# M440 register map
File version: 0.1
Registers are 32-bit, read-write, reset 0x0 unless marked. A register's access mark holds for its fields unless they carry their own. Offsets are from the block's base; [hi:lo] are bit positions; {n}, {i} and the like mark numbered series.

## PN — Port N
Base 0x400C0C00
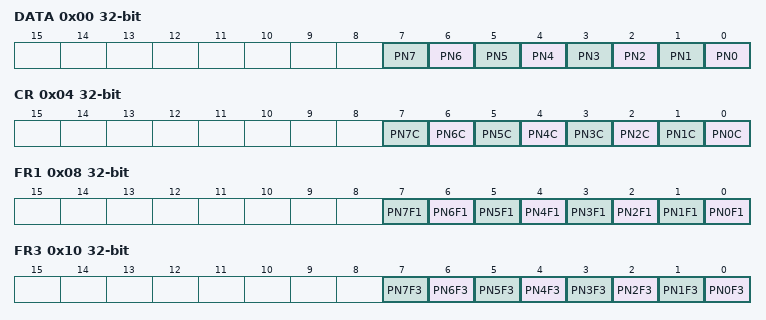
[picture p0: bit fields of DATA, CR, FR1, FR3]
0x00 DATA — Port N Data Register
  [n] PN{n} (n=0..7)
0x04 CR — Port N Output Control Register
  [n] PN{n}C (n=0..7)
0x08 FR1 — Port N Function Register 1
  [n] PN{n}F1 (n=0..7)
0x10 FR3 — Port N Function Register 3
  [n] PN{n}F3 (n=0..7)
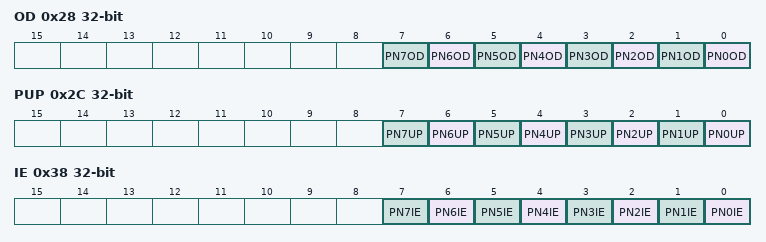
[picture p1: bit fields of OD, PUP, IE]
0x28 OD — Port N Open Drain Control Register
  [n] PN{n}OD (n=0..7)
0x2C PUP — Port N Pull-up Control Register
  [n] PN{n}UP (n=0..7)
0x38 IE — Port N Input Control Register
  [n] PN{n}IE (n=0..7)

## PP — Port P
Base 0x400C0D00
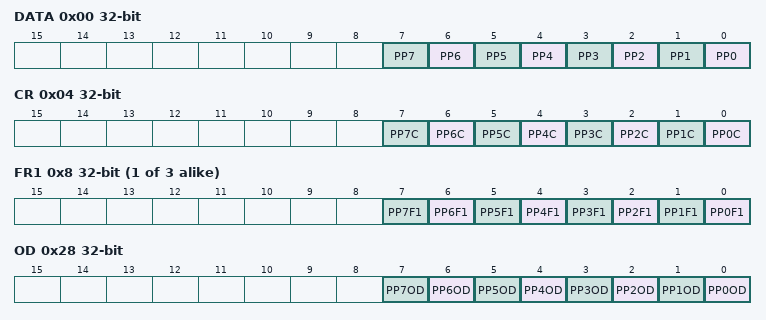
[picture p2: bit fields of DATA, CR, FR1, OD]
0x00 DATA — Port P Data Register
  [n] PP{n} (n=0..7)
0x04 CR — Port P Output Control Register
  [n] PP{n}C (n=0..7)
{0x4+4i} FR{i} (i=1..3) — Port P Function Register {i}
  [n] PP{n}F{i} (n=0..7)
0x28 OD — Port P Open Drain Control Register
  [n] PP{n}OD (n=0..7)
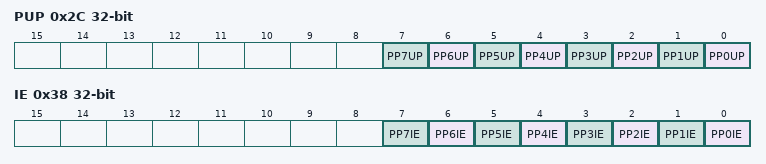
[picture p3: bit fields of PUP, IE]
0x2C PUP — Port P Pull-up Control Register
  [n] PP{n}UP (n=0..7)
0x38 IE — Port P Input Control Register
  [n] PP{n}IE (n=0..7)

## PR — Port R
Base 0x400C0E00
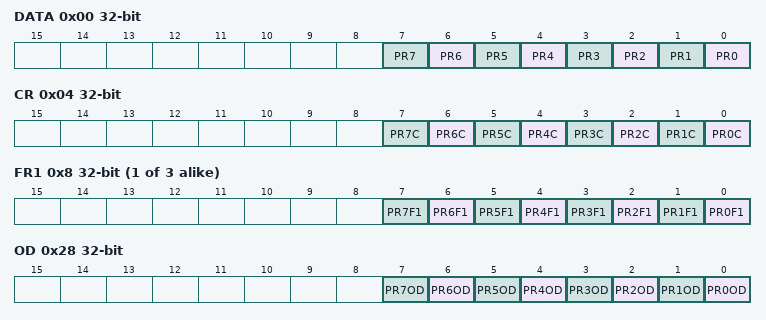
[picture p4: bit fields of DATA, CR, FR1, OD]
0x00 DATA — Port R Data Register
  [n] PR{n} (n=0..7)
0x04 CR — Port R Output Control Register
  [n] PR{n}C (n=0..7)
{0x4+4i} FR{i} (i=1..3) — Port R Function Register {i}
  [n] PR{n}F{i} (n=0..7)
0x28 OD — Port R Open Drain Control Register
  [n] PR{n}OD (n=0..7)
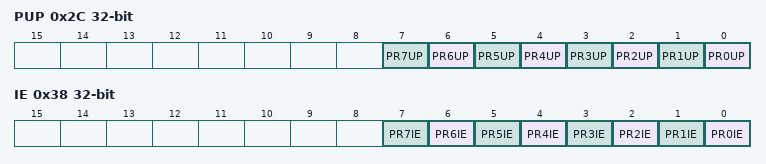
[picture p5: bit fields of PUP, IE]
0x2C PUP — Port R Pull-up Control Register
  [n] PR{n}UP (n=0..7)
0x38 IE — Port R Input Control Register
  [n] PR{n}IE (n=0..7)

## PT — Port T
Base 0x400C0F00
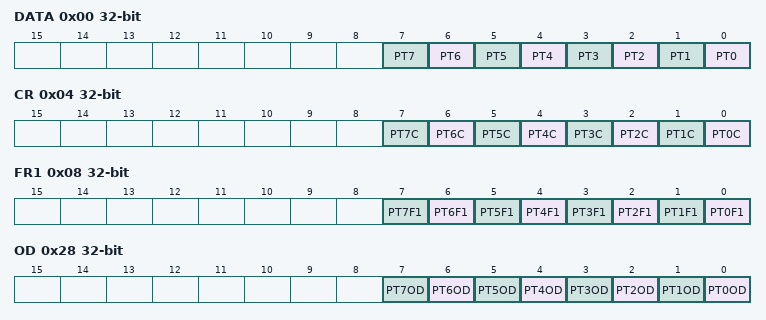
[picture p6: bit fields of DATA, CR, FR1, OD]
0x00 DATA — Port T Data Register
  [n] PT{n} (n=0..7)
0x04 CR — Port T Output Control Register
  [n] PT{n}C (n=0..7)
0x08 FR1 — Port T Function Register 1
  [n] PT{n}F1 (n=0..7)
0x28 OD — Port T Open Drain Control Register
  [n] PT{n}OD (n=0..7)
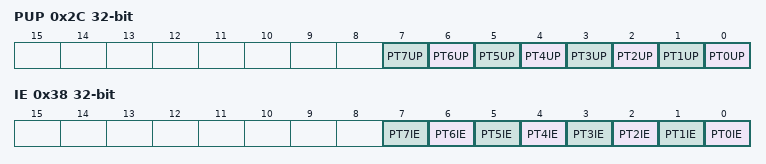
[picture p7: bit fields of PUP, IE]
0x2C PUP — Port T Pull-up Control Register
  [n] PT{n}UP (n=0..7)
0x38 IE — Port T Input Control Register
  [n] PT{n}IE (n=0..7)

## PU — Port U
Base 0x400C1000
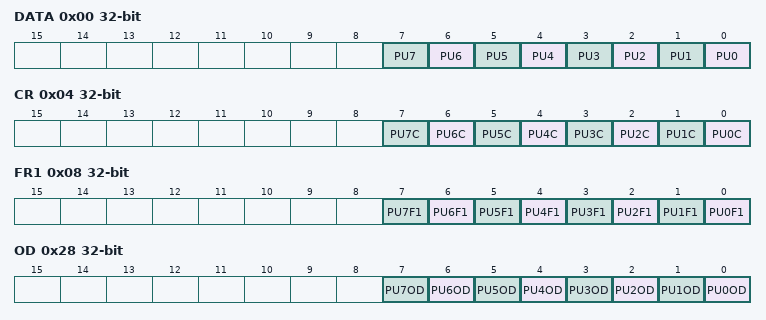
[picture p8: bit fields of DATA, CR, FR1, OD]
0x00 DATA — Port U Data Register
  [n] PU{n} (n=0..7)
0x04 CR — Port U Output Control Register
  [n] PU{n}C (n=0..7)
0x08 FR1 — Port U Function Register 1
  [n] PU{n}F1 (n=0..7)
0x28 OD — Port U Open Drain Control Register
  [n] PU{n}OD (n=0..7)
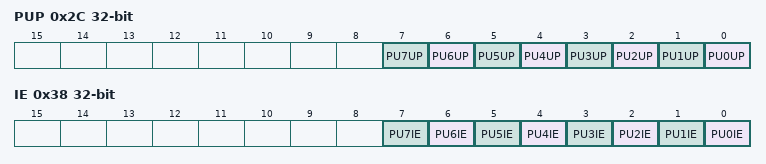
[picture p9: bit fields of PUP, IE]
0x2C PUP — Port U Pull-up Control Register
  [n] PU{n}UP (n=0..7)
0x38 IE — Port U Input Control Register
  [n] PU{n}IE (n=0..7)

## PV — Port V
Base 0x400C1100
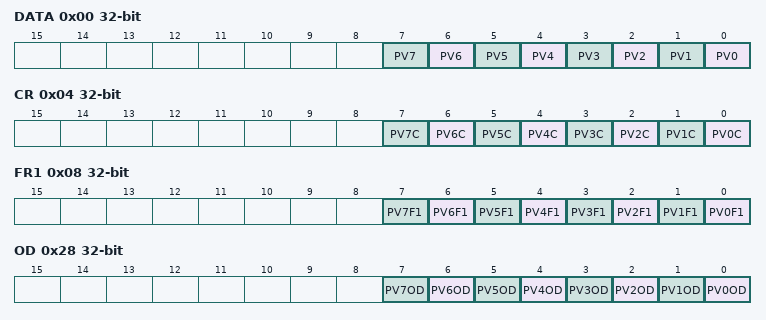
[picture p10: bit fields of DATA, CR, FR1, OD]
0x00 DATA — Port V Data Register
  [n] PV{n} (n=0..7)
0x04 CR — Port V OutPVt Control Register
  [n] PV{n}C (n=0..7)
0x08 FR1 — Port V Function Register 1
  [n] PV{n}F1 (n=0..7)
0x28 OD — Port V Open Drain Control Register
  [n] PV{n}OD (n=0..7)
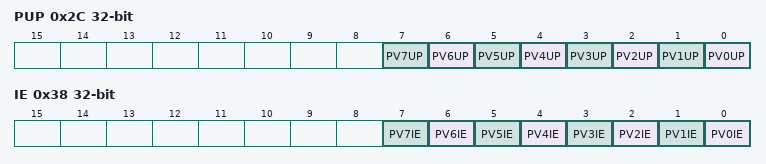
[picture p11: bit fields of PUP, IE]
0x2C PUP — Port V PVll-up Control Register
  [n] PV{n}UP (n=0..7)
0x38 IE — Port V InPVt Control Register
  [n] PV{n}IE (n=0..7)

## PW — Port W
Base 0x400C1200
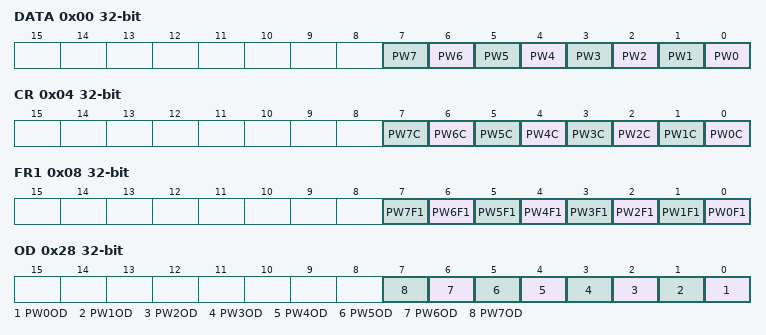
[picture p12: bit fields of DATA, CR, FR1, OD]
0x00 DATA — Port W Data Register
  [n] PW{n} (n=0..7)
0x04 CR — Port W OutPWt Control Register
  [n] PW{n}C (n=0..7)
0x08 FR1 — Port W Function Register 1
  [n] PW{n}F1 (n=0..7)
0x28 OD — Port W Open Drain Control Register
  [n] PW{n}OD (n=0..7)
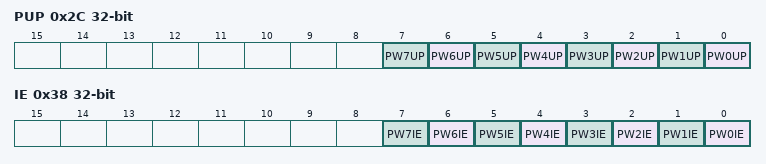
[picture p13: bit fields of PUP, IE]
0x2C PUP — Port W PWll-up Control Register
  [n] PW{n}UP (n=0..7)
0x38 IE — Port W InPWt Control Register
  [n] PW{n}IE (n=0..7)

## PY — Port Y
Base 0x400C1300
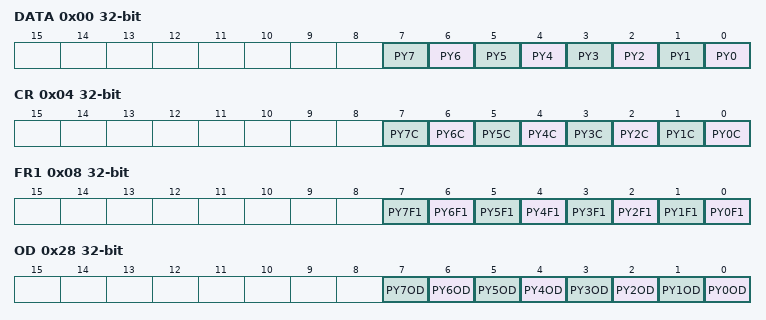
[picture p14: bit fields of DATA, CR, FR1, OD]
0x00 DATA — Port Y Data Register
  [n] PY{n} (n=0..7)
0x04 CR — Port Y OutPYt Control Register
  [n] PY{n}C (n=0..7)
0x08 FR1 — Port Y Function Register 1
  [n] PY{n}F1 (n=0..7)
0x28 OD — Port Y Open Drain Control Register
  [n] PY{n}OD (n=0..7)
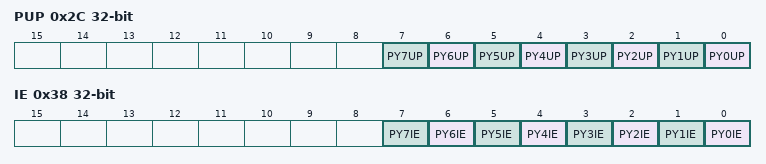
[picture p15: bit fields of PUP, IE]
0x2C PUP — Port Y PYll-up Control Register
  [n] PY{n}UP (n=0..7)
0x38 IE — Port Y InPYt Control Register
  [n] PY{n}IE (n=0..7)

## PAA — Port AA
Base 0x400C1400
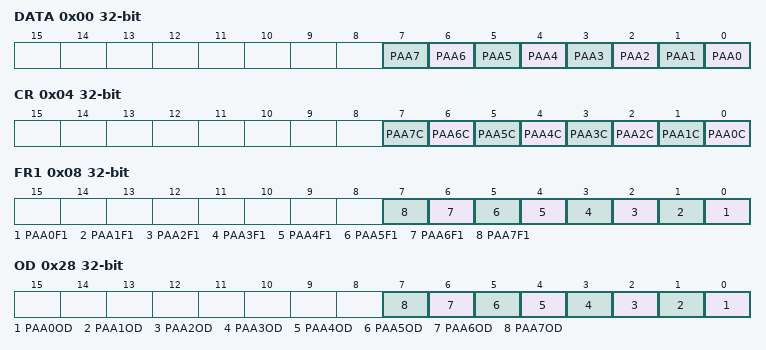
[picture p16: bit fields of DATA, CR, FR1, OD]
0x00 DATA — Port AA Data Register
  [n] PAA{n} (n=0..7)
0x04 CR — Port AA OutPAAt Control Register
  [n] PAA{n}C (n=0..7)
0x08 FR1 — Port AA Function Register 1
  [n] PAA{n}F1 (n=0..7)
0x28 OD — Port AA Open Drain Control Register
  [n] PAA{n}OD (n=0..7)
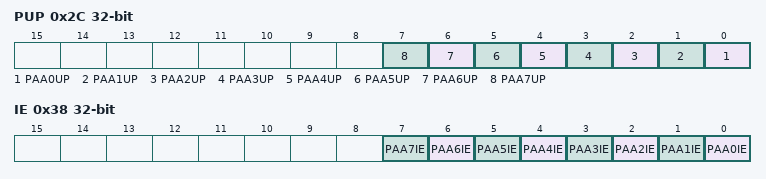
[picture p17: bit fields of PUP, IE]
0x2C PUP — Port AA PAAll-up Control Register
  [n] PAA{n}UP (n=0..7)
0x38 IE — Port AA InPAAt Control Register
  [n] PAA{n}IE (n=0..7)
